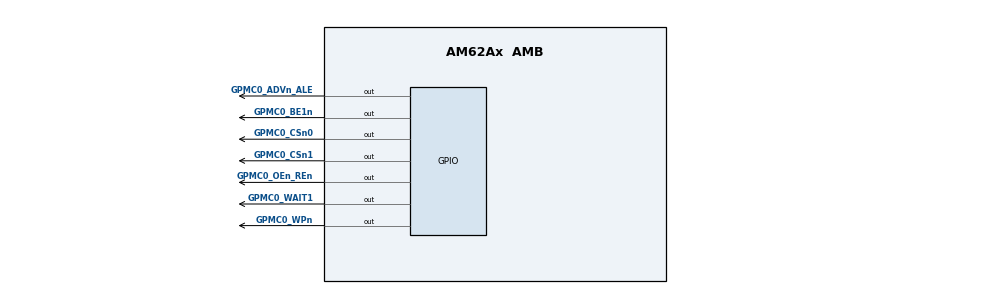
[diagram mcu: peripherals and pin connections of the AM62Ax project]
/**
 * @cliArgs --device "AM62Ax" --part "Default" --package "AMB" --context "r5fss0-0" --product "MCU_PLUS_SDK@07.03.01"
 * @versions {"tool":"1.26.2+4477"}
 */

/**
 * Import the modules used in this configuration.
 */
const eqep        = scripting.addModule("/drivers/eqep/eqep", {}, false);
const eqep1       = eqep.addInstance();
const eqep2       = eqep.addInstance();
const eqep3       = eqep.addInstance();
const gpio        = scripting.addModule("/drivers/gpio/gpio", {}, false);
const gpio1       = gpio.addInstance();
const gpio2       = gpio.addInstance();
const gpio3       = gpio.addInstance();
const gpio4       = gpio.addInstance();
const gpio5       = gpio.addInstance();
const gpio6       = gpio.addInstance();
const gpio7       = gpio.addInstance();
const i2c         = scripting.addModule("/drivers/i2c/i2c", {}, false);
const i2c1        = i2c.addInstance();
const ipc         = scripting.addModule("/drivers/ipc/ipc");
const uart        = scripting.addModule("/drivers/uart/uart", {}, false);
const uart1       = uart.addInstance();
const clock       = scripting.addModule("/kernel/dpl/clock");
const debug_log   = scripting.addModule("/kernel/dpl/debug_log");
const mpu_armv7   = scripting.addModule("/kernel/dpl/mpu_armv7", {}, false);
const mpu_armv71  = mpu_armv7.addInstance();
const mpu_armv72  = mpu_armv7.addInstance();
const mpu_armv73  = mpu_armv7.addInstance();
const mpu_armv74  = mpu_armv7.addInstance();
const mpu_armv75  = mpu_armv7.addInstance();
const mpu_armv76  = mpu_armv7.addInstance();
const mpu_armv77  = mpu_armv7.addInstance();
const mpu_armv78  = mpu_armv7.addInstance();
const mpu_armv79  = mpu_armv7.addInstance();
const mpu_armv710 = mpu_armv7.addInstance();
const mpu_armv711 = mpu_armv7.addInstance();
const mpu_armv712 = mpu_armv7.addInstance();

/**
 * Write custom configuration values to the imported modules.
 */
eqep1.$name          = "CONFIG_EQEP0";
eqep1.EQEP.$assign   = "EQEP2";
eqep1.EQEP.A.$assign = "I2C0_SCL";
eqep1.EQEP.B.$assign = "I2C0_SDA";
eqep1.EQEP.I.$assign = "MCAN0_TX";
eqep1.EQEP.S.$assign = "MCAN0_RX";

eqep2.$name          = "CONFIG_EQEP1";
eqep2.EQEP.$assign   = "EQEP1";
eqep2.EQEP.A.$assign = "MCASP0_ACLKX";
eqep2.EQEP.B.$assign = "MCASP0_AFSX";
eqep2.EQEP.I.$assign = "MCASP0_ACLKR";
eqep2.EQEP.S.$assign = "MCASP0_AFSR";

eqep3.$name          = "CONFIG_EQEP2";
eqep3.EQEP.$assign   = "EQEP0";
eqep3.EQEP.A.$assign = "MCASP0_AXR3";
eqep3.EQEP.B.$assign = "MCASP0_AXR2";
eqep3.EQEP.I.$assign = "MCASP0_AXR0";
eqep3.EQEP.S.$assign = "MCASP0_AXR1";

gpio1.$name                = "CONFIG_GPIO0";
gpio1.pinDir               = "OUTPUT";
gpio1.GPIO.gpioPin.rx      = false;
gpio1.GPIO.gpioPin.$assign = "GPMC0_WAIT1";

gpio2.$name                = "CONFIG_GPIO1";
gpio2.pinDir               = "OUTPUT";
gpio2.GPIO.gpioPin.rx      = false;
gpio2.GPIO.gpioPin.$assign = "GPMC0_WPn";

gpio3.$name                = "CONFIG_GPIO2";
gpio3.pinDir               = "OUTPUT";
gpio3.GPIO.gpioPin.rx      = false;
gpio3.GPIO.gpioPin.$assign = "GPMC0_ADVn_ALE";

gpio4.$name                = "CONFIG_GPIO3";
gpio4.pinDir               = "OUTPUT";
gpio4.GPIO.gpioPin.rx      = false;
gpio4.GPIO.gpioPin.$assign = "GPMC0_OEn_REn";

gpio5.$name                = "CONFIG_GPIO4";
gpio5.pinDir               = "OUTPUT";
gpio5.GPIO.gpioPin.rx      = false;
gpio5.GPIO.gpioPin.$assign = "GPMC0_CSn0";

gpio6.$name                = "CONFIG_GPIO5";
gpio6.pinDir               = "OUTPUT";
gpio6.GPIO.gpioPin.rx      = false;
gpio6.GPIO.gpioPin.$assign = "GPMC0_CSn1";

gpio7.$name                = "CONFIG_GPIO6";
gpio7.pinDir               = "OUTPUT";
gpio7.GPIO.gpioPin.rx      = false;
gpio7.GPIO.gpioPin.$assign = "GPMC0_BE1n";

i2c1.$name                      = "CONFIG_I2C0";
i2c1.useWakeupDomainPeripherals = false;
i2c1.I2C_child.$name            = "drivers_i2c_v0_i2c_v0_template0";
i2c1.I2C.$assign                = "I2C1";

ipc.enableLinuxIpc = false;
ipc.a53ss0_0       = "notify";
ipc.c75ss0_0       = "notify";
ipc.mcu_r5fss0_0   = "NONE";

uart1.$name                      = "CONFIG_UART_SBL";
uart1.useWakeupDomainPeripherals = false;
uart1.intrEnable                 = "DISABLE";

debug_log.enableUartLog            = true;
debug_log.enableSharedMemLog       = true;
debug_log.enableSharedMemLogReader = true;
debug_log.enableCssLog             = false;
debug_log.uartTrace                = true;
debug_log.uartLog.$name            = "CONFIG_UART0";

mpu_armv71.accessPermissions = "Supervisor RD+WR, User RD";
mpu_armv71.allowExecute      = false;
mpu_armv71.size              = 31;
mpu_armv71.attributes        = "Device";
mpu_armv71.$name             = "REGISTER_REGION";

mpu_armv72.accessPermissions = "Supervisor RD+WR, User RD";
mpu_armv72.size              = 7;
mpu_armv72.$name             = "TCMA_VEC";

mpu_armv73.$name             = "CONFIG_MPU_REGION2";
mpu_armv73.accessPermissions = "Supervisor RD+WR, User RD";
mpu_armv73.baseAddr          = 0x41C00000;
mpu_armv73.size              = 19;

mpu_armv74.$name             = "CONFIG_MPU_REGION3";
mpu_armv74.accessPermissions = "Supervisor RD+WR, User RD";
mpu_armv74.baseAddr          = 0x70000000;
mpu_armv74.size              = 16;

mpu_armv75.$name    = "DDR";
mpu_armv75.baseAddr = 0x80000000;
mpu_armv75.size     = 31;

mpu_armv76.baseAddr   = 0x41010000;
mpu_armv76.size       = 15;
mpu_armv76.attributes = "NonCached";
mpu_armv76.$name      = "TCMB";

mpu_armv77.size       = 15;
mpu_armv77.attributes = "NonCached";
mpu_armv77.$name      = "TCMA";

mpu_armv78.baseAddr = 0x43C00000;
mpu_armv78.size     = 18;
mpu_armv78.$name    = "HSM_RAM";

mpu_armv79.$name      = "RING_BUFFER";
mpu_armv79.baseAddr   = 0x9C800000;
mpu_armv79.attributes = "NonCached";
mpu_armv79.size       = 21;

mpu_armv710.attributes   = "NonCached";
mpu_armv710.size         = 20;
mpu_armv710.allowExecute = false;
mpu_armv710.$name        = "RESOURCE_TABLE";
mpu_armv710.baseAddr     = 0x9D900000;

mpu_armv711.$name        = "RTOS_NORTOS_IPC_VRING";
mpu_armv711.baseAddr     = 0xA0000000;
mpu_armv711.size         = 23;
mpu_armv711.allowExecute = false;
mpu_armv711.attributes   = "NonCached";

mpu_armv712.$name      = "LOG_SHM_MEM";
mpu_armv712.baseAddr   = 0xA1000000;
mpu_armv712.attributes = "NonCached";
mpu_armv712.size       = 18;

/**
 * Pinmux solution for unlocked pins/peripherals. This ensures that minor changes to the automatic solver in a future
 * version of the tool will not impact the pinmux you originally saw.  These lines can be completely deleted in order to
 * re-solve from scratch.
 */
gpio1.GPIO.$suggestSolution                      = "GPIO0";
gpio2.GPIO.$suggestSolution                      = "GPIO0";
gpio3.GPIO.$suggestSolution                      = "GPIO0";
gpio4.GPIO.$suggestSolution                      = "GPIO0";
gpio5.GPIO.$suggestSolution                      = "GPIO0";
gpio6.GPIO.$suggestSolution                      = "GPIO0";
gpio7.GPIO.$suggestSolution                      = "GPIO0";
i2c1.I2C.SCL.$suggestSolution                    = "I2C1_SCL";
i2c1.I2C.SDA.$suggestSolution                    = "I2C1_SDA";
uart1.UART.$suggestSolution                      = "USART0";
uart1.UART.RXD.$suggestSolution                  = "UART0_RXD";
uart1.UART.TXD.$suggestSolution                  = "UART0_TXD";
debug_log.uartLog.WKUP_UART.$suggestSolution     = "WKUP_USART0";
debug_log.uartLog.WKUP_UART.RXD.$suggestSolution = "WKUP_UART0_RXD";
debug_log.uartLog.WKUP_UART.TXD.$suggestSolution = "WKUP_UART0_TXD";
